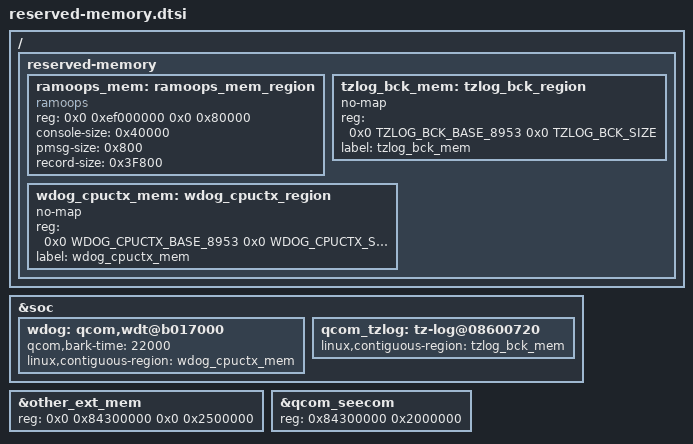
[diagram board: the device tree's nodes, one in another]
/ {
	reserved-memory {
		ramoops_mem: ramoops_mem_region {
			compatible = "ramoops";
			reg = <0x0 0xef000000 0x0 0x80000>;
			console-size = <0x40000>;
			pmsg-size = <0x800>;
			record-size = <0x3F800>;
		};

		tzlog_bck_mem: tzlog_bck_region {
			no-map;
			reg = <0x0 TZLOG_BCK_BASE_8953
				0x0 TZLOG_BCK_SIZE>;
			label = "tzlog_bck_mem";
		};

		wdog_cpuctx_mem: wdog_cpuctx_region {
			no-map;
			reg = <0x0 WDOG_CPUCTX_BASE_8953
				0x0 WDOG_CPUCTX_SIZE_8953>;
			label = "wdog_cpuctx_mem";
		};
	};
};

&soc {
	wdog: qcom,wdt@b017000 {
		qcom,bark-time = <22000>;
		linux,contiguous-region = <&wdog_cpuctx_mem>;
	};

	qcom_tzlog: tz-log@08600720 {
		status = "okay";
		linux,contiguous-region = <&tzlog_bck_mem>;
	};
};

&other_ext_mem {
	reg = <0x0 0x84300000 0x0 0x2500000>;
};

&qcom_seecom {
	reg = <0x84300000 0x2000000>;
};
